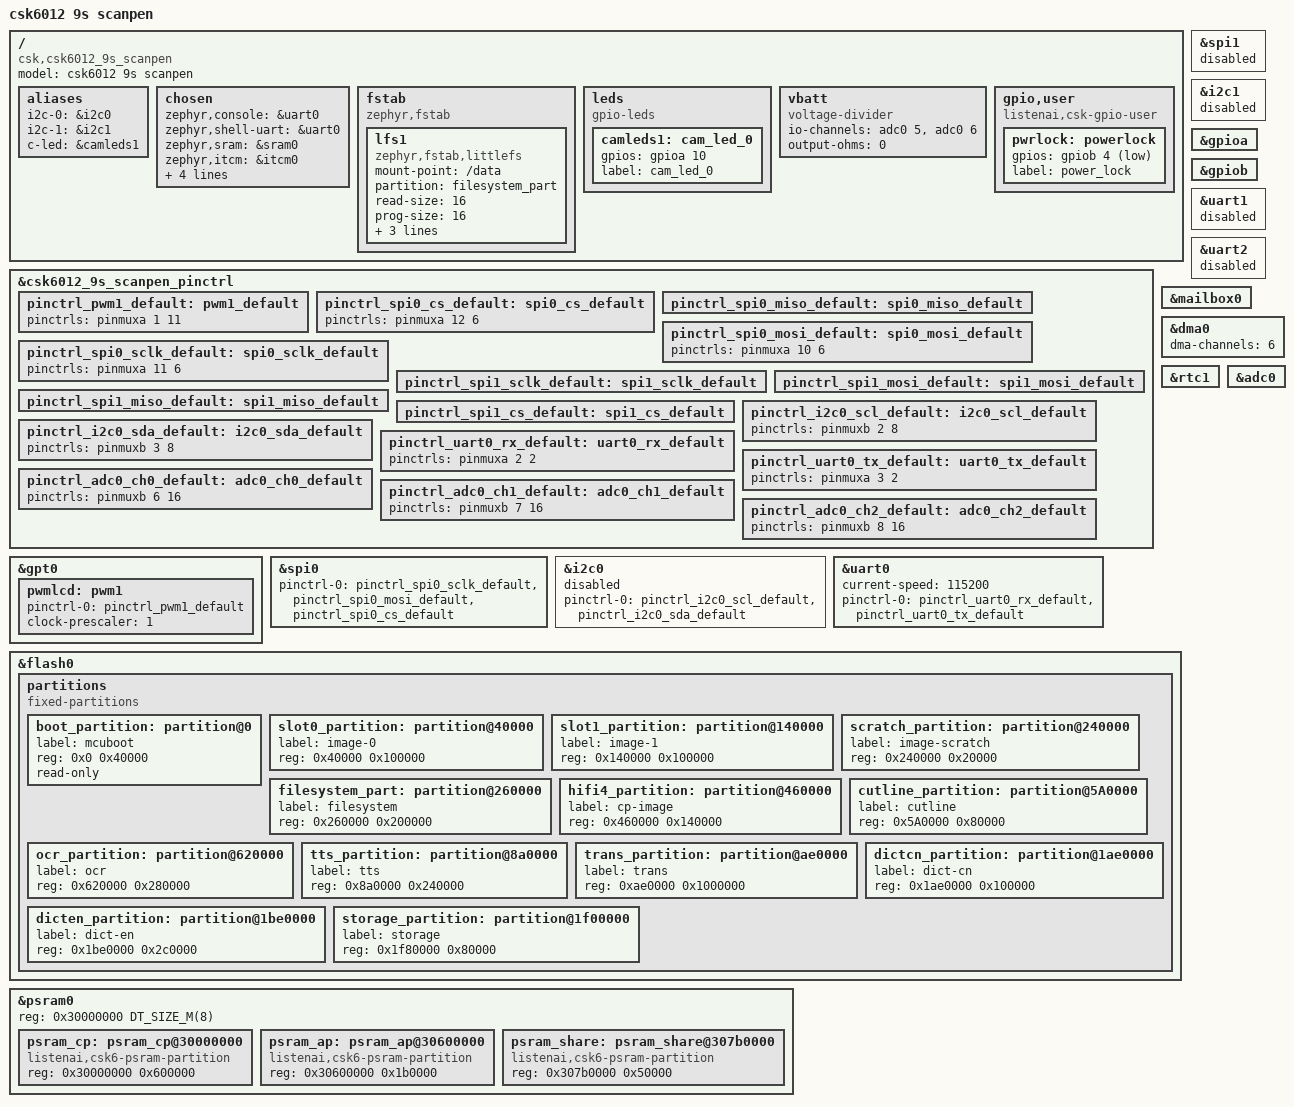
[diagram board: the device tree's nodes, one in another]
/* SPDX-License-Identifier: Apache-2.0 */

/dts-v1/;
#include <csk/csk6.dtsi>
#include <dt-bindings/pwm/pwm.h>
#include "csk6012_9s_scanpen_pinctrl.dtsi"

&csk6012_9s_scanpen_pinctrl{
        pinctrl_pwm1_default: pwm1_default{
                pinctrls = <&pinmuxa 1 11>;
        };
        /* SPIC alternate function */
        pinctrl_spi0_cs_default: spi0_cs_default{
                pinctrls = <&pinmuxa 12 6>;
        };

        pinctrl_spi0_miso_default: spi0_miso_default{
        };

        pinctrl_spi0_mosi_default: spi0_mosi_default{
                pinctrls = <&pinmuxa 10 6>;
        };

        pinctrl_spi0_sclk_default: spi0_sclk_default{
                pinctrls = <&pinmuxa 11 6>;
        };
        
        pinctrl_spi1_sclk_default: spi1_sclk_default{
        };
        
        pinctrl_spi1_mosi_default: spi1_mosi_default{
        };

        pinctrl_spi1_miso_default: spi1_miso_default{
        };    

        pinctrl_spi1_cs_default: spi1_cs_default{
        };

        /* I2C alternate function */
        pinctrl_i2c0_scl_default: i2c0_scl_default{
                pinctrls = <&pinmuxb 2 8>;
        };
        
        pinctrl_i2c0_sda_default: i2c0_sda_default{
                pinctrls = <&pinmuxb 3 8>;
        };
        /* UART alternate function */
        pinctrl_uart0_rx_default: uart0_rx_default{
                pinctrls = <&pinmuxa 2 2>;
        };
        
        pinctrl_uart0_tx_default: uart0_tx_default{
                pinctrls = <&pinmuxa 3 2>;
        };

        /* ADC alternate function */
        pinctrl_adc0_ch0_default: adc0_ch0_default{
                pinctrls = <&pinmuxb 6 16>;
        };
        
        pinctrl_adc0_ch1_default: adc0_ch1_default{
                pinctrls = <&pinmuxb 7 16>;
        };

        pinctrl_adc0_ch2_default: adc0_ch2_default{
                pinctrls = <&pinmuxb 8 16>;
        };
        
};

/ {
        model = "csk6012 9s scanpen";
        compatible = "csk,csk6012_9s_scanpen";
        aliases {
                // led0 = &board_led_2;
                i2c-0 = &i2c0;
                i2c-1 = &i2c1;
                c-led = &camleds1;
        };

        chosen {
                zephyr,console = &uart0;
                zephyr,shell-uart = &uart0;
                zephyr,sram = &sram0;
                zephyr,itcm = &itcm0;
                zephyr,dtcm = &dtcm0;
                zephyr,flash = &flash0;
                zephyr,flash_sysfs_storage = &filesystem_part;
		zephyr,flash_controller = &flash;
                /* other chosen settings  for your hardware */
        };

        fstab {
		compatible = "zephyr,fstab";
		lfs1: lfs1 {
			compatible = "zephyr,fstab,littlefs";
			mount-point = "/data";
			partition = <&filesystem_part>;
			read-size = <16>;
			prog-size = <16>;
			cache-size = <64>;
			lookahead-size = <32>;
			block-cycles = <512>;
		};
	};

        leds {
                compatible = "gpio-leds";
                camleds1: cam_led_0 {
                        gpios = <&gpioa 10 0>;
                        label = "cam_led_0";
                };

        };

        vbatt {
                compatible = "voltage-divider";
		io-channels = <&adc0 5>, <&adc0 6>;
		output-ohms = <0>;
	};

        gpio,user {
                compatible = "listenai,csk-gpio-user";
                pwrlock: powerlock {
                        gpios = <&gpiob 4 1>;
                        label = "power_lock";
                };

        };

};
&gpt0 {
	status = "okay";
	pwmlcd: pwm1 {
                pinctrl-0 = <&pinctrl_pwm1_default>; 
                pinctrl-names = "default";
                clock-prescaler = <1>;
                status = "okay";
	};
};

&spi0 {
        status = "okay";
        pinctrl-0 = <&pinctrl_spi0_sclk_default &pinctrl_spi0_mosi_default &pinctrl_spi0_cs_default>; 
        pinctrl-names = "default";
};
&spi1 {
    status = "disabled";

};
&i2c0 {
        status = "disabled";
        pinctrl-0 = <&pinctrl_i2c0_scl_default &pinctrl_i2c0_sda_default>; 
        pinctrl-names = "default";
};

&i2c1 {
    status = "disabled";
};

&gpioa {
        status = "okay";
};

&gpiob {
        status = "okay";
};


&uart0 {
        current-speed = <115200>;
        pinctrl-0 = <&pinctrl_uart0_rx_default &pinctrl_uart0_tx_default>; 
        pinctrl-names = "default";
	// pinmux-names = "RXD", "TXD";
        status = "okay";
};
&uart1 {
        status = "disabled";
};

&uart2 {
        status = "disabled";
};

&mailbox0 {
	status = "okay";
};
&dma0 {
	dma-channels = <6>;
	status = "okay";
};

&rtc1 {
        status = "okay";
};
&adc0 {
        status = "okay";
};

&flash0 {
        /*
         * For more information, see:
         * http: //docs.zephyrproject.org/latest/guides/dts/index.html#flash-partitions
         */
        partitions {
                compatible = "fixed-partitions";
                #address-cells = <1>;
                #size-cells = <1>;

                /* 256KB for bootloader */
                boot_partition: partition@0 {
                        label = "mcuboot";
                        reg = <0x0 0x40000>;
                        read-only;
                };

                /* application image slot: 1024KB */
                slot0_partition: partition@40000 {
                        label = "image-0";
                        reg = <0x40000 0x100000>;
                };

                /* backup slot: 1024KB */
                slot1_partition: partition@140000 {
                        label = "image-1";
                        reg = <0x140000 0x100000>;
                };

                /* swap slot: 128KB */
                scratch_partition: partition@240000 {
                        label = "image-scratch";
                        reg = <0x240000 0x20000>;
                };

                /* filesystem: Kb */
                filesystem_part: partition@260000 {
                        label = "filesystem";
                        reg = <0x260000 0x200000>;
                };

                /* cp partition: 3MB  */
                hifi4_partition: partition@460000 {
                        label = "cp-image";
                        reg = <0x460000 0x140000>;
                };

				/*cutline partition: 512K */
                cutline_partition: partition@5A0000 {
                        label = "cutline";
                        reg = <0x5A0000 0x80000>;
                };

				/*ocr partition: 2.5M */
                ocr_partition: partition@620000 {
                        label = "ocr";
                        reg = <0x620000 0x280000>;
                };

				/*tts partition: 4M */
                tts_partition: partition@8a0000 {
                        label = "tts";
                        reg = <0x8a0000 0x240000>;
                };

				/*trans partition: 16M */
                trans_partition: partition@ae0000 {
                        label = "trans";
                        reg = <0xae0000 0x1000000>;
                };

				/*dict_cn */
                dictcn_partition: partition@1ae0000 {
                        label = "dict-cn";
                        reg = <0x1ae0000 0x100000>;
                };

				/*dict_en */
                dicten_partition: partition@1be0000 {
                        label = "dict-en";
                        reg = <0x1be0000 0x2c0000>;
                };

				/* Reserve the final 512 KiB*/
                storage_partition: partition@1f00000 {
                                label = "storage";
                                reg = <0x1f80000 0x80000>;
                };
        };
};

&psram0 {
        reg = <0x30000000 DT_SIZE_M(8)>;
        #address-cells = <1>;
        #size-cells = <1>;

        /*psram for cp core slot: 6MB */
        psram_cp:psram_cp@30000000{
                compatible = "listenai,csk6-psram-partition";
                reg = <0x30000000 0x600000>;
                status = "okay";
        };

        /*psram for ap core slot: 1MB */
        psram_ap: psram_ap@30600000 {
                compatible = "listenai,csk6-psram-partition";
                reg = <0x30600000 0x1b0000>;
                status = "okay";
        };

        /*psram for ap share with cp slot: 512KB */
        psram_share: psram_share@307b0000 {
                compatible = "listenai,csk6-psram-partition";
                reg = <0x307b0000 0x50000>;
                status = "okay";
        };
};
